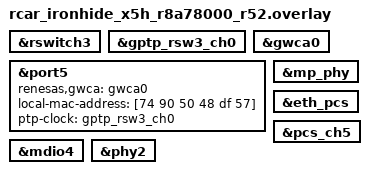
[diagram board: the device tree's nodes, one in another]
/*
 * Copyright (c) 2026 Renesas Electronics Corporation
 *
 * SPDX-License-Identifier: Apache-2.0
 */

/*
 * gPTP on port5 through R-Switch 3: the port net_if transfers through
 * GWCA0 and timestamps with timer 0 of the R-Switch 3 gPTP block. For
 * gPTP on TSN-ES4 instead, see rcar_ironhide_x5h_r8a78000_r52_tsnes4.overlay.
 */

&rswitch3 {
	status = "okay";
};

&gptp_rsw3_ch0 {
	status = "okay";
};

&gwca0 {
	status = "okay";
};

&port5 {
	status = "okay";
	renesas,gwca = <&gwca0>;
	local-mac-address = [74 90 50 48 df 57];
	ptp-clock = <&gptp_rsw3_ch0>;
};

&mp_phy {
	status = "okay";
};

&eth_pcs {
	status = "okay";
};

&pcs_ch5 {
	status = "okay";
};

&mdio4 {
	status = "okay";
};

&phy2 {
	status = "okay";
};
